# ref_a register map
Vendor: Texas Instruments
Peripheral module from a debugger description file (folder MSP432).
Registers are 16-bit, read-write, no defined reset value unless marked. A register's access mark holds for its fields unless they carry their own. Offsets are as the file gives them; lines under a group give offsets from that group; [hi:lo] are bit positions; {n}, {i} and the like mark numbered series; 'fields as' and 'values as' point back to an identical list; <NAME> marks a mode.

## REF_A
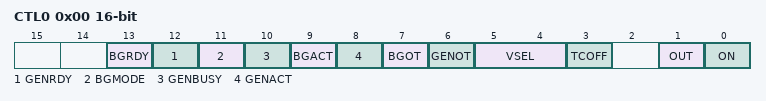
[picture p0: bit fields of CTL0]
0x00 CTL0 — REF Control Register 0
  [13] BGRDY — Buffered bandgap voltage ready status.
    0=BGRDY__0 (Buffered bandgap voltage is not ready to be used); 1=BGRDY__1 (Buffered bandgap voltage is ready to be used)
  [12] GENRDY — Variable reference voltage ready status.
    0=GENRDY__0 (Reference voltage output is not ready to be used); 1=GENRDY__1 (Reference voltage output is ready to be used)
  [11] BGMODE — Bandgap mode.
    0=BGMODE__0 (Static mode); 1=BGMODE__1 (Sampled mode)
  [10] GENBUSY — Reference generator busy.
    0=GENBUSY__0 (Reference generator not busy); 1=GENBUSY__1 (Reference generator busy)
  [9] BGACT — Reference bandgap active.
    0=BGACT__0 (Reference bandgap buffer not active); 1=BGACT__1 (Reference bandgap buffer active)
  [8] GENACT — Reference generator active.
    0=GENACT__0 (Reference generator not active); 1=GENACT__1 (Reference generator active)
  [7] BGOT — Bandgap and bandgap buffer one-time trigger
    0=BGOT__0 (No trigger); 1=BGOT__1 (Generation of the bandgap voltage is started by writing 1 or by)
  [6] GENOT — Reference generator one-time trigger
    0=GENOT__0 (No trigger); 1=GENOT__1 (Generation of the reference voltage is started by writing 1 or)
  [5:4] VSEL — Reference voltage level select
    0=VSEL__0 (1.2 V available when reference requested or REFON = 1); 1=VSEL__1 (1.45 V available when reference requested or REFON = 1); 3=VSEL__3 (2.5 V available when reference requested or REFON = 1)
  [3] TCOFF — Temperature sensor disabled
    0=TCOFF__0 (Temperature sensor enabled); 1=TCOFF__1 (Temperature sensor disabled to save power)
  [1] OUT — Reference output buffer
    0=OUT__0 (Reference output not available externally); 1=OUT__1 (Reference output available externally)
  [0] ON — Reference enable. Can be modified only when REFGENBUSY = 0.
    0=ON__0 (Disables reference if no other reference requests are pending); 1=ON__1 (Enables reference in static mode)
